# ZB204 register map
Vendor: GS; File version: 1.2
ARM 32-bit Cortex-M4 Microcontroller based device, CPU clock up to 80MHz, etc.
CPU: CM3 r2p0, little endian, MPU, no FPU, VTOR, 3 interrupt priority bits
Registers are 32-bit, read-write, reset 0x0 unless marked. A register's access mark holds for its fields unless they carry their own. Offsets are from the block's base; lines under a group give offsets from that group; [hi:lo] are bit positions; {n}, {i} and the like mark numbered series; 'fields as' and 'values as' point back to an identical list; <NAME> marks a mode.

## Memory map
0x40010000 CCM size 0x30 — Chip Configuration Module
0x40020000 RESET size 0x4 — Reset Controller Module
0x40030000 CPM size 0x40 — Clock and Power Control Module
0x40040000 PORTS size 0x200 — Port Configuration
0x40060000 ADC size 0x50 — Analog-to-digital converter
0x40070000 PIT_CONTROL0 size 0x100 — Programmable Interrupt Timer Modules
0x40070100 PIT_CHANNEL0 size 0x10 — Programmable Interrupt Timer Modules
0x40070110 PIT_CHANNEL1 size 0x10
0x40070120 PIT_CHANNEL2 size 0x10
0x40070130 PIT_CHANNEL3 size 0x10
0x40070140 PIT_CHANNEL4 size 0x10
0x40070150 PIT_CHANNEL5 size 0x10
0x40080000 PIT_CONTROL1 size 0x100
0x40080100 PIT_CHANNEL6 size 0x10
0x40080110 PIT_CHANNEL7 size 0x10
0x40080120 PIT_CHANNEL8 size 0x10
0x40080130 PIT_CHANNEL9 size 0x10
0x40080140 PIT_CHANNEL10 size 0x10
0x40080150 PIT_CHANNEL11 size 0x10
0x40090000 QSPI size 0xA500 — QuadSPI
0x400A0000 SPI0 size 0x20 — Serial Peripheral Interface Module
0x400B0000 SPI1 size 0x20
0x400C0000 I2C size 0x10 — two-wire bidirectional serial bus
0x400D0000 SCI0 size 0x20 — Serial Communications Interface Module
0x400E0000 SCI1 size 0x20
0x400F0000 SCI2 size 0x20
0x40100000 SCI3 size 0x20
0x40140000 EPORT0 size 0x10 — Edge Port Module
{0x40140000+0x10000*n} EPORT{n} size 0x10 (n=1..9)
0x401E0000 SWT size 0x20 — Software Watchdog Timer
0x40300000 DMAC size 0x1000 — AMBA AHB module
0x40400000 CRC size 0x10
0x40500000 BPLC size 0xFFF
0x40503000 BPLC_SB_SNR size 0xFFF — BPLC snr
0x40600000 AES size 0x50
0x40900000 HRF size 0x30C
0x40A00000 PWM0 size 0x70 — Pulse Width Modulator
0x40B00000 PWM1 size 0x70

## Interrupts
0 DMA (DMAC) — DMA interrupt
1 BPLC_NTB_TIMER (BPLC_SB_SNR)
2 BPLC — BPLC interrupt
3 SPI0 — SPI interrupt
4 SPI1 — SPI1 interrupt
5 I2C0 (I2C) — I2C interrupt
6 SCI0 — UART interrupt
7 SCI1 — UART interrupt
8 SCI2 — UART interrupt
9 SCI3 — UART interrupt
10 PWM0 — PWM interrupt
11 PWM1 — PWM interrupt
13 AES — AES interrupt
15 HRF — HRF interrupt
16 SWT — SWT interrupt
17 QSPI — QSPI interrupt
{n+20} EPORT{n} (n=0..9) — EOPRT interrupt
{n+30} PIT{n} (PIT_CHANNEL{n}) (n=0..11) — PIT interrupt
42 CMP (CPM) — CMP interrupt
43 LVD (CPM) — LVD interrupt

## RESET — Reset Controller Module
Base 0x40020000
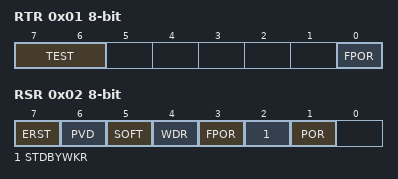
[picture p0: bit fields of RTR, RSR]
0x01 RTR 8-bit — Reset Test Register
  [7:6] TEST — Write Access Enable Sequence Input
  [0] FPOR — Force Power On Reset
0x02 RSR 8-bit — Reset Status Register
  [7] ERST — Watchdog Timer Prescaler
  [6] PVD ro — Watchdog Interrupt Flag Bit
  [5] SOFT ro — Watchdog Change Update Bit
  [4] WDR ro — Watchdog Change Update Bit
  [3] FPOR ro — Force Power-On Reset Flag
  [2] STDBYWKR ro — Standby Wakeup Reset Flag
  [1] POR ro — Watchdog Enable Bit
0x03 RCR 8-bit — Reset Control Register
  [0] FRCRSTOUT — Force RESET PIN
    0=Negate bit; 1=Assert bit

## Licence text in the file
ARM Limited (ARM) is supplying this software for use with Cortex-M processor based microcontroller, but can be equally used for other suitable processor architectures. This file can be freely distributed. Modifications to this file shall be clearly marked. . THIS SOFTWARE IS PROVIDED "AS IS". NO WARRANTIES, WHETHER EXPRESS, IMPLIED. OR STATUTORY, INCLUDING, BUT NOT LIMITED TO, IMPLIED WARRANTIES OF. MERCHANTABILITY AND FITNESS FOR A PARTICULAR PURPOSE APPLY TO THIS SOFTWARE. ARM SHALL NOT, IN ANY CIRCUMSTANCES, BE LIABLE FOR SPECIAL, INCIDENTAL, OR. CONSEQUENTIAL DAMAGES, FOR ANY REASON WHATSOEVER.

## Notices in the file
Copyright (C) 2012 ARM Limited. All rights reserved.
Purpose: System Viewer Description (SVD) Example (Schema Version 1.1)
This is a description of a none-existent and incomplete device
for demonstration purposes only.
Redistribution and use in source and binary forms, with or without
modification, are permitted provided that the following conditions are met:
- Redistributions of source code must retain the above copyright
notice, this list of conditions and the following disclaimer.
- Redistributions in binary form must reproduce the above copyright
notice, this list of conditions and the following disclaimer in the
documentation and/or other materials provided with the distribution.
- Neither the name of ARM nor the names of its contributors may be used
to endorse or promote products derived from this software without
specific prior written permission.
THIS SOFTWARE IS PROVIDED BY THE COPYRIGHT HOLDERS AND CONTRIBUTORS "AS IS"
AND ANY EXPRESS OR IMPLIED WARRANTIES, INCLUDING, BUT NOT LIMITED TO, THE
ARE DISCLAIMED. IN NO EVENT SHALL COPYRIGHT HOLDERS AND CONTRIBUTORS BE
LIABLE FOR ANY DIRECT, INDIRECT, INCIDENTAL, SPECIAL, EXEMPLARY, OR
CONSEQUENTIAL DAMAGES (INCLUDING, BUT NOT LIMITED TO, PROCUREMENT OF
SUBSTITUTE GOODS OR SERVICES; LOSS OF USE, DATA, OR PROFITS; OR BUSINESS
INTERRUPTION) HOWEVER CAUSED AND ON ANY THEORY OF LIABILITY, WHETHER IN
CONTRACT, STRICT LIABILITY, OR TORT (INCLUDING NEGLIGENCE OR OTHERWISE)
ARISING IN ANY WAY OUT OF THE USE OF THIS SOFTWARE, EVEN IF ADVISED OF THE
POSSIBILITY OF SUCH DAMAGE.
